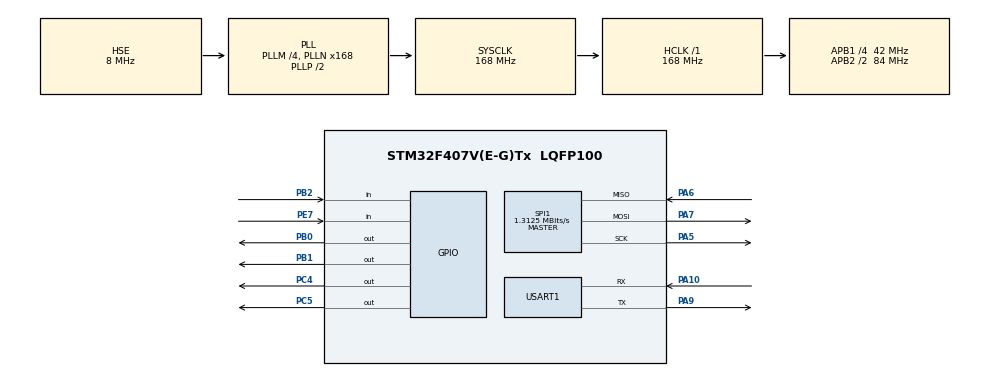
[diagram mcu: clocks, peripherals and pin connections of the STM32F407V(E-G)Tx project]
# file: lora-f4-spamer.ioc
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Mcu.Family=STM32F4
RCC.PLLSourceVirtual=RCC_PLLSOURCE_HSE
PA6.Mode=Full_Duplex_Master
PH0-OSC_IN.Signal=RCC_OSC_IN
RCC.CortexFreq_Value=168000000
PA7.Mode=Full_Duplex_Master
PA10.Mode=Asynchronous
SPI1.VirtualType=VM_MASTER
PC4.PinState=GPIO_PIN_RESET
PC4.Signal=GPIO_Output
RCC.APB1CLKDivider=RCC_HCLK_DIV4
RCC.SYSCLKSource=RCC_SYSCLKSOURCE_PLLCLK
ProjectManager.StackSize=0x400
PA13.Signal=SYS_JTMS-SWDIO
PA9.Mode=Asynchronous
ProjectManager.TargetToolchain=STM32CubeIDE
SPI1.Direction=SPI_DIRECTION_2LINES
RCC.HCLKFreq_Value=168000000
RCC.APB2TimFreq_Value=168000000
PA9.Signal=USART1_TX
SPI1.CalculateBaudRate=1.3125 MBits/s
RCC.LSE_VALUE=32768
RCC.AHBFreq_Value=168000000
PH0-OSC_IN.Mode=HSE-External-Oscillator
PA5.Signal=SPI1_SCK
RCC.HSE_VALUE=8000000
PB2.Signal=GPIO_Input
board=custom
RCC.VCOOutputFreq_Value=336000000
RCC.APB2Freq_Value=84000000
SPI1.Mode=SPI_MODE_MASTER
PA14.Mode=Serial_Wire
PH1-OSC_OUT.Signal=RCC_OSC_OUT
PA13.Mode=Serial_Wire
Mcu.Name=STM32F407V(E-G)Tx
PH1-OSC_OUT.Mode=HSE-External-Oscillator
RCC.48MHZClocksFreq_Value=84000000
RCC.SYSCLKFreq_VALUE=168000000
Mcu.Package=LQFP100
PA6.Signal=SPI1_MISO
PB1.Signal=GPIO_Output
RCC.EnbaleCSS=true
USART1.VirtualMode=VM_ASYNC
PA10.Signal=USART1_RX
PA14.Signal=SYS_JTCK-SWCLK
ProjectManager.HeapSize=0x200
RCC.HSI_VALUE=16000000
NVIC.PriorityGroup=NVIC_PRIORITYGROUP_4
RCC.APB2CLKDivider=RCC_HCLK_DIV2
RCC.PLLM=4
RCC.PLLN=168
RCC.APB1TimFreq_Value=84000000
PC5.Signal=GPIO_Output
PE7.Signal=GPIO_Input
RCC.APB1Freq_Value=42000000
SPI1.BaudRatePrescaler=SPI_BAUDRATEPRESCALER_64
PB0.Signal=GPIO_Output
PA5.Mode=Full_Duplex_Master
PA7.Signal=SPI1_MOSI

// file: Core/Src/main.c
/* USER CODE BEGIN Header */
/**
  ******************************************************************************
  * @file           : main.c
  * @brief          : Main program body
  ******************************************************************************
  * @attention
  *
  * <h2><center>&copy; Copyright (c) 2021 STMicroelectronics.
  * All rights reserved.</center></h2>
  *
  * This software component is licensed by ST under BSD 3-Clause license,
  * the "License"; You may not use this file except in compliance with the
  * License. You may obtain a copy of the License at:
  *                        opensource.org/licenses/BSD-3-Clause
  *
  ******************************************************************************
  */
/* USER CODE END Header */
#include "main.h"

SPI_HandleTypeDef hspi1;

UART_HandleTypeDef huart1;

void SystemClock_Config(void);
static void MX_GPIO_Init(void);
static void MX_SPI1_Init(void);
static void MX_USART1_UART_Init(void);

/* USER CODE BEGIN 0 */
int app_main(void);
/* USER CODE END 0 */

int main(void)
{

  /* MCU Configuration--------------------------------------------------------*/

  /* Reset of all peripherals, Initializes the Flash interface and the Systick. */
  HAL_Init();

  /* Configure the system clock */
  SystemClock_Config();

  /* Initialize all configured peripherals */
  MX_GPIO_Init();
  MX_SPI1_Init();
  MX_USART1_UART_Init();

  /* Infinite loop */
  /* USER CODE BEGIN WHILE */
  app_main();
  return 0;
  while (1)
  {
    /* USER CODE END WHILE */

  }
}

void SystemClock_Config(void)
{
  RCC_OscInitTypeDef RCC_OscInitStruct = {0};
  RCC_ClkInitTypeDef RCC_ClkInitStruct = {0};

  /** Configure the main internal regulator output voltage
  */
  __HAL_RCC_PWR_CLK_ENABLE();
  __HAL_PWR_VOLTAGESCALING_CONFIG(PWR_REGULATOR_VOLTAGE_SCALE1);
  /** Initializes the RCC Oscillators according to the specified parameters
  * in the RCC_OscInitTypeDef structure.
  */
  RCC_OscInitStruct.OscillatorType = RCC_OSCILLATORTYPE_HSE;
  RCC_OscInitStruct.HSEState = RCC_HSE_ON;
  RCC_OscInitStruct.PLL.PLLState = RCC_PLL_ON;
  RCC_OscInitStruct.PLL.PLLSource = RCC_PLLSOURCE_HSE;
  RCC_OscInitStruct.PLL.PLLM = 4;
  RCC_OscInitStruct.PLL.PLLN = 168;
  RCC_OscInitStruct.PLL.PLLP = RCC_PLLP_DIV2;
  RCC_OscInitStruct.PLL.PLLQ = 4;
  if (HAL_RCC_OscConfig(&RCC_OscInitStruct) != HAL_OK)
  {
    Error_Handler();
  }
  /** Initializes the CPU, AHB and APB buses clocks
  */
  RCC_ClkInitStruct.ClockType = RCC_CLOCKTYPE_HCLK|RCC_CLOCKTYPE_SYSCLK
                              |RCC_CLOCKTYPE_PCLK1|RCC_CLOCKTYPE_PCLK2;
  RCC_ClkInitStruct.SYSCLKSource = RCC_SYSCLKSOURCE_PLLCLK;
  RCC_ClkInitStruct.AHBCLKDivider = RCC_SYSCLK_DIV1;
  RCC_ClkInitStruct.APB1CLKDivider = RCC_HCLK_DIV4;
  RCC_ClkInitStruct.APB2CLKDivider = RCC_HCLK_DIV2;

  if (HAL_RCC_ClockConfig(&RCC_ClkInitStruct, FLASH_LATENCY_5) != HAL_OK)
  {
    Error_Handler();
  }
  /** Enables the Clock Security System
  */
  HAL_RCC_EnableCSS();
}

static void MX_SPI1_Init(void)
{

  /* SPI1 parameter configuration*/
  hspi1.Instance = SPI1;
  hspi1.Init.Mode = SPI_MODE_MASTER;
  hspi1.Init.Direction = SPI_DIRECTION_2LINES;
  hspi1.Init.DataSize = SPI_DATASIZE_8BIT;
  hspi1.Init.CLKPolarity = SPI_POLARITY_LOW;
  hspi1.Init.CLKPhase = SPI_PHASE_1EDGE;
  hspi1.Init.NSS = SPI_NSS_SOFT;
  hspi1.Init.BaudRatePrescaler = SPI_BAUDRATEPRESCALER_64;
  hspi1.Init.FirstBit = SPI_FIRSTBIT_MSB;
  hspi1.Init.TIMode = SPI_TIMODE_DISABLE;
  hspi1.Init.CRCCalculation = SPI_CRCCALCULATION_DISABLE;
  hspi1.Init.CRCPolynomial = 10;
  if (HAL_SPI_Init(&hspi1) != HAL_OK)
  {
    Error_Handler();
  }

}

static void MX_USART1_UART_Init(void)
{

  huart1.Instance = USART1;
  huart1.Init.BaudRate = 115200;
  huart1.Init.WordLength = UART_WORDLENGTH_8B;
  huart1.Init.StopBits = UART_STOPBITS_1;
  huart1.Init.Parity = UART_PARITY_NONE;
  huart1.Init.Mode = UART_MODE_TX_RX;
  huart1.Init.HwFlowCtl = UART_HWCONTROL_NONE;
  huart1.Init.OverSampling = UART_OVERSAMPLING_16;
  if (HAL_UART_Init(&huart1) != HAL_OK)
  {
    Error_Handler();
  }

}

static void MX_GPIO_Init(void)
{
  GPIO_InitTypeDef GPIO_InitStruct = {0};

  /* GPIO Ports Clock Enable */
  __HAL_RCC_GPIOH_CLK_ENABLE();
  __HAL_RCC_GPIOA_CLK_ENABLE();
  __HAL_RCC_GPIOC_CLK_ENABLE();
  __HAL_RCC_GPIOB_CLK_ENABLE();
  __HAL_RCC_GPIOE_CLK_ENABLE();

  /*Configure GPIO pin Output Level */
  HAL_GPIO_WritePin(GPIOC, GPIO_PIN_4|GPIO_PIN_5, GPIO_PIN_RESET);

  /*Configure GPIO pin Output Level */
  HAL_GPIO_WritePin(GPIOB, GPIO_PIN_0|GPIO_PIN_1, GPIO_PIN_RESET);

  /*Configure GPIO pins : PC4 PC5 */
  GPIO_InitStruct.Pin = GPIO_PIN_4|GPIO_PIN_5;
  GPIO_InitStruct.Mode = GPIO_MODE_OUTPUT_PP;
  GPIO_InitStruct.Pull = GPIO_NOPULL;
  GPIO_InitStruct.Speed = GPIO_SPEED_FREQ_LOW;
  HAL_GPIO_Init(GPIOC, &GPIO_InitStruct);

  /*Configure GPIO pins : PB0 PB1 */
  GPIO_InitStruct.Pin = GPIO_PIN_0|GPIO_PIN_1;
  GPIO_InitStruct.Mode = GPIO_MODE_OUTPUT_PP;
  GPIO_InitStruct.Pull = GPIO_NOPULL;
  GPIO_InitStruct.Speed = GPIO_SPEED_FREQ_LOW;
  HAL_GPIO_Init(GPIOB, &GPIO_InitStruct);

  /*Configure GPIO pin : PB2 */
  GPIO_InitStruct.Pin = GPIO_PIN_2;
  GPIO_InitStruct.Mode = GPIO_MODE_INPUT;
  GPIO_InitStruct.Pull = GPIO_NOPULL;
  HAL_GPIO_Init(GPIOB, &GPIO_InitStruct);

  /*Configure GPIO pin : PE7 */
  GPIO_InitStruct.Pin = GPIO_PIN_7;
  GPIO_InitStruct.Mode = GPIO_MODE_INPUT;
  GPIO_InitStruct.Pull = GPIO_NOPULL;
  HAL_GPIO_Init(GPIOE, &GPIO_InitStruct);

}

void Error_Handler(void)
{
  __disable_irq();
  while (1)
  {
  }
}

/************************ (C) COPYRIGHT STMicroelectronics *****END OF FILE****/
